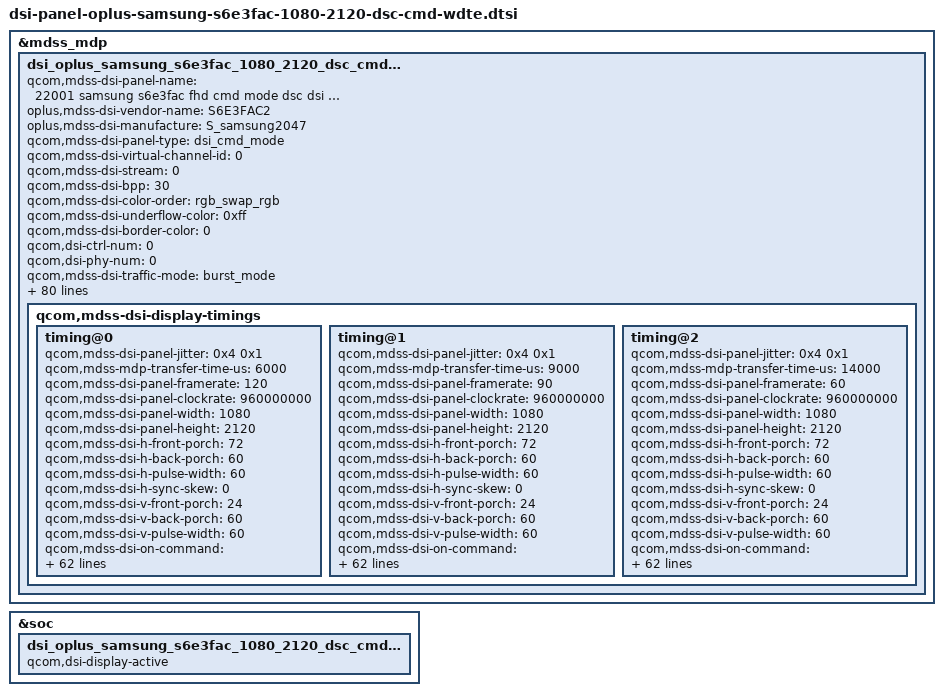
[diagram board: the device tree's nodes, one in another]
&mdss_mdp {
	dsi_oplus_samsung_s6e3fac_1080_2120_dsc_cmd_wdte: qcom,mdss_dsi_oplus_samsung_s6e3fac_1080_2120_dsc_cmd_wdte {
		qcom,mdss-dsi-panel-name = "22001 samsung s6e3fac fhd cmd mode dsc dsi panel";
		oplus,mdss-dsi-vendor-name = "S6E3FAC2";
		oplus,mdss-dsi-manufacture = "S_samsung2047";

		qcom,mdss-dsi-panel-type = "dsi_cmd_mode";
		qcom,mdss-dsi-virtual-channel-id = <0>;
		qcom,mdss-dsi-stream = <0>;
		qcom,mdss-dsi-bpp = <30>;
		qcom,mdss-dsi-color-order = "rgb_swap_rgb";
		qcom,mdss-dsi-underflow-color = <0xff>;
		qcom,mdss-dsi-border-color = <0>;
		qcom,dsi-ctrl-num = <0>;
		qcom,dsi-phy-num = <0>;
		qcom,mdss-dsi-traffic-mode = "burst_mode";
		qcom,mdss-dsi-lane-map = "lane_map_0123";
		qcom,mdss-dsi-bllp-eof-power-mode;
		qcom,mdss-dsi-bllp-power-mode;
		qcom,mdss-dsi-lane-0-state;
		qcom,mdss-dsi-lane-1-state;
		qcom,mdss-dsi-lane-2-state;
		qcom,mdss-dsi-lane-3-state;
		qcom,mdss-dsi-dma-trigger = "trigger_sw";
		qcom,mdss-loading-effect;
		qcom,mdss-dsi-mdp-trigger = "none";
		qcom,mdss-dsi-reset-sequence = <1 10>, <0 10>, <1 10>;
		qcom,mdss-dsi-te-pin-select = <1>;
		qcom,mdss-dsi-te-dcs-command = <1>;
		qcom,mdss-pan-physical-width-dimension = <64>;
		qcom,mdss-pan-physical-height-dimension = <125>;
		qcom,mdss-dsi-init-delay-us = <1000>;
		qcom,mdss-dsi-te-check-enable;
		qcom,mdss-dsi-te-using-te-pin;
		qcom,mdss-dsi-lp11-init;
		qcom,mdss-dsi-wr-mem-start = <0x2c>;
		qcom,mdss-dsi-wr-mem-continue = <0x3c>;
		qcom,mdss-dsi-panel-jitter = <0x4 0x1>;
		/* HDR Setting */
		qcom,mdss-dsi-panel-hdr-enabled;
		qcom,mdss-dsi-panel-hdr-color-primaries = <15635 16450 34000 16000 13250 34500 7500 3000>;
		qcom,mdss-dsi-panel-peak-brightness = <5400000>;
		qcom,mdss-dsi-panel-average-brightness = <2000000>;
		qcom,mdss-dsi-panel-blackness-level = <4000>;

		qcom,mdss-dsi-display-timings {
			timing@0{
				qcom,mdss-dsi-panel-jitter = <0x4 0x1>;
				qcom,mdss-mdp-transfer-time-us = <6000>;
				qcom,mdss-dsi-panel-framerate = <120>;
				qcom,mdss-dsi-panel-clockrate = <960000000>;
				qcom,mdss-dsi-panel-width = <1080>;
				qcom,mdss-dsi-panel-height = <2120>;
				qcom,mdss-dsi-h-front-porch = <72>;
				qcom,mdss-dsi-h-back-porch = <60>;
				qcom,mdss-dsi-h-pulse-width = <60>;
				qcom,mdss-dsi-h-sync-skew = <0>;
				qcom,mdss-dsi-v-front-porch = <24>;
				qcom,mdss-dsi-v-back-porch = <60>;
				qcom,mdss-dsi-v-pulse-width = <60>;

				qcom,mdss-dsi-on-command = [
					/* DSC Setting */
					39 01 00 00 00 00 02 9D 01
					39 01 00 00 00 00 5A 9E
					   11 00 00 89 30 80 08 48 04 38
					   00 28 02 1C 02 1C 02 00 02 3B
					   00 20 03 92 00 07 00 0E 02 E0
					   02 8B 18 00 10 F0 03 0C 20 00
					   06 0B 0B 33 0E 1C 2A 38 46 54
					   62 69 70 77 79 7B 7D 7E 01 02
					   01 00 09 40 09 BE 19 FC 19 FA
					   19 F8 1A 38 1A 78 1A B6 2A B6
					   2A F4 2A F4 4B 34 63 74 00
					/* Sleep Out(11h) */
					05 01 00 00 78 00 01 11
					/* TE ON */
					15 01 00 00 00 00 02 35 00
					/* CASET/PASET Setting */
					39 01 00 00 00 00 05 2A 00 00 04 37
					39 01 00 00 00 00 05 2B 00 00 08 47
					/* 120hz Transition */
					39 01 00 00 00 00 03 F0 5A 5A
					39 01 00 00 00 00 02 60 00
					39 01 00 00 00 00 02 F7 0F
					39 01 00 00 00 00 03 F0 A5 A5
					/* Brightness Control */
					39 01 00 00 00 00 03 F0 5A 5A
					15 01 00 00 00 00 02 53 20
					15 01 00 00 00 00 02 F7 0F
					39 01 00 00 00 00 03 F0 A5 A5
					/* auto flash */
					//39 01 00 00 00 00 03 F0 5A 5A
					//39 01 00 00 00 00 02 BF 02
					//39 01 00 00 00 00 03 F0 A5 A5
					/* Display On */
					//05 01 00 00 14 00 01 29
				];
				qcom,mdss-dsi-timing-switch-command = [
					/* 120hz Transition */
					39 01 00 00 00 00 03 F0 5A 5A
					39 01 00 00 00 00 02 60 00
					39 01 00 00 00 00 02 F7 0F
					39 01 00 00 10 00 03 F0 A5 A5
				];
				qcom,mdss-dsi-post-on-backlight = [
					/* Display On */
					05 01 00 00 00 00 01 29
				];
				qcom,mdss-dsi-off-command = [
					/* Display Off */
					05 01 00 00 14 00 01 28
					05 01 00 00 79 00 01 10
				];

				qcom,mdss-dsi-lp1-command = [
					05 00 00 00 09 00 01 28
					/* AOD Mode ON Setting */
					39 00 00 40 00 00 03 F0 5A 5A
					15 00 00 40 00 00 02 53 24
					39 00 00 40 00 00 03 51 07 FF
					15 00 00 40 00 00 02 F7 0F
					39 00 00 00 00 00 03 F0 A5 A5
					05 00 00 00 00 00 01 29
				];
				qcom,mdss-dsi-nolp-command = [
					05 00 00 00 09 00 01 28
					/* AOD Mode OFF Setting */
					39 00 00 40 00 00 03 F0 5A 5A
					15 00 00 40 00 00 02 60 00
					15 00 00 40 00 00 02 53 20
					39 00 00 40 00 00 03 51 00 00
					15 00 00 40 00 00 02 F7 0F
					39 00 00 00 00 00 03 F0 A5 A5
					05 00 00 00 00 00 01 29
				];
				qcom,mdss-dsi-aod-high-mode-command = [
					/* AOD High Mode, 50nit */
					39 00 00 40 00 00 03 F0 5A 5A
					39 00 00 40 00 00 03 51 07 FF
					15 00 00 40 00 00 02 F7 0F
					39 00 00 00 00 00 03 F0 A5 A5
				];
				qcom,mdss-dsi-aod-low-mode-command = [
					/* AOD Low Mode 10nit */
					39 00 00 40 00 00 03 F0 5A 5A
					39 00 00 40 00 00 03 51 01 AA
					15 00 00 40 00 00 02 F7 0F
					39 00 00 00 00 00 03 F0 A5 A5
				];

				qcom,mdss-dsi-loading-effect-1-command = [
					/* LOADING 100% */
					39 00 00 40 00 00 03 F0 5A 5A
					39 00 00 40 00 00 04 B0 02 79 92
					39 00 00 40 00 00 02 92 27
					39 00 00 40 00 00 04 B0 02 88 92
					39 00 00 40 00 00 10 92 05 06 05 17 19 16 1F 21 1E 25 27 24 27 2A 26
					39 00 00 40 00 00 04 B0 03 61 92
					39 00 00 40 00 00 12 92 E2 0E 0E 0E 92 1D 98 80 00 00 00 00 FF 90 00 00 01
					39 00 00 00 00 00 03 F0 A5 A5
				];
				qcom,mdss-dsi-loading-effect-2-command = [
					/* LOADING 110% */
					39 00 00 40 00 00 03 F0 5A 5A
					39 00 00 40 00 00 04 B0 02 79 92
					39 00 00 40 00 00 02 92 27
					39 00 00 40 00 00 04 B0 02 88 92
					39 00 00 40 00 00 10 92 05 06 05 17 19 16 1F 21 1E 25 27 24 27 2A 26
					39 00 00 40 00 00 04 B0 03 61 92
					39 00 00 40 00 00 12 92 E2 09 09 09 92 1D 98 80 76 5E 5B 49 FF 90 00 00 01
					39 00 00 00 00 00 03 F0 A5 A5
				];
				qcom,mdss-dsi-loading-effect-off-command = [
					/* LOADING off */
					39 00 00 40 00 00 03 F0 5A 5A
					39 00 00 40 00 00 04 B0 02 79 92
					39 00 00 40 00 00 02 92 07
					39 00 00 00 00 00 03 F0 A5 A5
				];

				qcom,mdss-dsi-panel-read-register-open-command = [
				];
				qcom,mdss-dsi-panel-read-register-close-command = [
				];

				qcom,mdss-dsi-lp1-command-state = "dsi_hs_mode";
				qcom,mdss-dsi-nolp-command-state = "dsi_hs_mode";
				qcom,mdss-dsi-aod-high-mode-command-state = "dsi_hs_mode";
				qcom,mdss-dsi-aod-low-mode-command-state = "dsi_hs_mode";
				qcom,mdss-dsi-loading-effect-1-command-state = "dsi_hs_mode";
				qcom,mdss-dsi-loading-effect-2-command-state = "dsi_hs_mode";
				qcom,mdss-dsi-loading-effect-off-command-state = "dsi_hs_mode";
				qcom,mdss-dsi-post-on-backlight-state = "dsi_hs_mode";
				qcom,mdss-dsi-on-command-state = "dsi_hs_mode";
				qcom,mdss-dsi-off-command-state = "dsi_hs_mode";
				qcom,mdss-dsi-osc-clk-mode0-command-state = "dsi_hs_mode";
				qcom,mdss-dsi-osc-clk-mode1-command-state = "dsi_hs_mode";

				qcom,compression-mode = "dsc";
				qcom,mdss-dsc-slice-height = <40>;
				qcom,mdss-dsc-slice-width = <540>;
				qcom,mdss-dsc-slice-per-pkt = <2>;
				qcom,mdss-dsc-bit-per-component = <8>;
				qcom,mdss-dsc-bit-per-pixel = <8>;
				qcom,mdss-dsc-block-prediction-enable;
				qcom,mdss-dsi-panel-id1-command-state = "dsi_lp_mode";
				qcom,mdss-dsi-panel-read-register-open-state = "dsi_hs_mode";
				qcom,mdss-dsi-panel-read-register-close-state = "dsi_hs_mode";
			};
			timing@1{
				qcom,mdss-dsi-panel-jitter = <0x4 0x1>;
				qcom,mdss-mdp-transfer-time-us = <9000>;
				qcom,mdss-dsi-panel-framerate = <90>;
				qcom,mdss-dsi-panel-clockrate = <960000000>;
				qcom,mdss-dsi-panel-width = <1080>;
				qcom,mdss-dsi-panel-height = <2120>;
				qcom,mdss-dsi-h-front-porch = <72>;
				qcom,mdss-dsi-h-back-porch = <60>;
				qcom,mdss-dsi-h-pulse-width = <60>;
				qcom,mdss-dsi-h-sync-skew = <0>;
				qcom,mdss-dsi-v-front-porch = <24>;
				qcom,mdss-dsi-v-back-porch = <60>;
				qcom,mdss-dsi-v-pulse-width = <60>;

				qcom,mdss-dsi-on-command = [
					/* DSC Setting */
					39 01 00 00 00 00 02 9D 01
					39 01 00 00 00 00 5A 9E
					   11 00 00 89 30 80 08 48 04 38
					   00 28 02 1C 02 1C 02 00 02 3B
					   00 20 03 92 00 07 00 0E 02 E0
					   02 8B 18 00 10 F0 03 0C 20 00
					   06 0B 0B 33 0E 1C 2A 38 46 54
					   62 69 70 77 79 7B 7D 7E 01 02
					   01 00 09 40 09 BE 19 FC 19 FA
					   19 F8 1A 38 1A 78 1A B6 2A B6
					   2A F4 2A F4 4B 34 63 74 00
					/* Sleep Out(11h) */
					05 01 00 00 78 00 01 11
					/* TE ON */
					15 01 00 00 00 00 02 35 00
					/* CASET/PASET Setting */
					39 01 00 00 00 00 05 2A 00 00 04 37
					39 01 00 00 00 00 05 2B 00 00 08 47
					/* 90hz Transition */
					39 01 00 00 00 00 03 F0 5A 5A
					39 01 00 00 00 00 02 60 10
					39 01 00 00 00 00 02 F7 0F
					39 01 00 00 00 00 03 F0 A5 A5
					/* Brightness Control */
					39 01 00 00 00 00 03 F0 5A 5A
					15 01 00 00 00 00 02 53 20
					15 01 00 00 00 00 02 F7 0F
					39 01 00 00 00 00 03 F0 A5 A5
					/* auto flash */
					//39 01 00 00 00 00 03 F0 5A 5A
					//39 01 00 00 00 00 02 BF 02
					//39 01 00 00 00 00 03 F0 A5 A5
					/* Display On */
					//05 01 00 00 14 00 01 29
				];
				qcom,mdss-dsi-timing-switch-command = [
					/* 90hz Transition */
					39 01 00 00 00 00 03 F0 5A 5A
					39 01 00 00 00 00 02 60 10
					39 01 00 00 00 00 02 F7 0F
					39 01 00 00 10 00 03 F0 A5 A5
				];
				qcom,mdss-dsi-post-on-backlight = [
					/* Display On */
					05 01 00 00 00 00 01 29
				];
				qcom,mdss-dsi-off-command = [
					/* Display Off */
					05 01 00 00 14 00 01 28
					05 01 00 00 79 00 01 10
				];

				qcom,mdss-dsi-lp1-command = [
					05 00 00 00 0C 00 01 28
					/* AOD Mode ON Setting */
					39 00 00 40 00 00 03 F0 5A 5A
					15 00 00 40 00 00 02 53 24
					39 00 00 40 00 00 03 51 07 FF
					15 00 00 40 00 00 02 F7 0F
					39 00 00 00 00 00 03 F0 A5 A5
					05 00 00 00 00 00 01 29
				];
				qcom,mdss-dsi-nolp-command = [
					05 00 00 00 0C 00 01 28
					/* AOD Mode OFF Setting */
					39 00 00 40 00 00 03 F0 5A 5A
					15 00 00 40 00 00 02 60 10
					15 00 00 40 00 00 02 53 20
					39 00 00 40 00 00 03 51 00 00
					15 00 00 40 00 00 02 F7 0F
					39 00 00 00 00 00 03 F0 A5 A5
					05 00 00 00 00 00 01 29
				];
				qcom,mdss-dsi-aod-high-mode-command = [
					/* AOD High Mode, 50nit */
					39 00 00 40 00 00 03 F0 5A 5A
					39 00 00 40 00 00 03 51 07 FF
					15 00 00 40 00 00 02 F7 0F
					39 00 00 00 00 00 03 F0 A5 A5
				];
				qcom,mdss-dsi-aod-low-mode-command = [
					/* AOD Low Mode 10nit */
					39 00 00 40 00 00 03 F0 5A 5A
					39 00 00 40 00 00 03 51 01 AA
					15 00 00 40 00 00 02 F7 0F
					39 00 00 00 00 00 03 F0 A5 A5
				];

				qcom,mdss-dsi-loading-effect-1-command = [
					/* LOADING 100% */
					39 00 00 40 00 00 03 F0 5A 5A
					39 00 00 40 00 00 04 B0 02 79 92
					39 00 00 40 00 00 02 92 27
					39 00 00 40 00 00 04 B0 02 88 92
					39 00 00 40 00 00 10 92 05 06 05 17 19 16 1F 21 1E 25 27 24 27 2A 26
					39 00 00 40 00 00 04 B0 03 61 92
					39 00 00 40 00 00 12 92 E2 0E 0E 0E 92 1D 98 80 00 00 00 00 FF 90 00 00 01
					39 00 00 00 00 00 03 F0 A5 A5
				];
				qcom,mdss-dsi-loading-effect-2-command = [
					/* LOADING 110% */
					39 00 00 40 00 00 03 F0 5A 5A
					39 00 00 40 00 00 04 B0 02 79 92
					39 00 00 40 00 00 02 92 27
					39 00 00 40 00 00 04 B0 02 88 92
					39 00 00 40 00 00 10 92 05 06 05 17 19 16 1F 21 1E 25 27 24 27 2A 26
					39 00 00 40 00 00 04 B0 03 61 92
					39 00 00 40 00 00 12 92 E2 09 09 09 92 1D 98 80 76 5E 5B 49 FF 90 00 00 01
					39 00 00 00 00 00 03 F0 A5 A5
				];
				qcom,mdss-dsi-loading-effect-off-command = [
					/* LOADING off */
					39 00 00 40 00 00 03 F0 5A 5A
					39 00 00 40 00 00 04 B0 02 79 92
					39 00 00 40 00 00 02 92 07
					39 00 00 00 00 00 03 F0 A5 A5
				];
				qcom,mdss-dsi-panel-read-register-open-command = [
				];
				qcom,mdss-dsi-panel-read-register-close-command = [
				];

				qcom,mdss-dsi-lp1-command-state = "dsi_hs_mode";
				qcom,mdss-dsi-nolp-command-state = "dsi_hs_mode";
				qcom,mdss-dsi-aod-high-mode-command-state = "dsi_hs_mode";
				qcom,mdss-dsi-aod-low-mode-command-state = "dsi_hs_mode";
				qcom,mdss-dsi-loading-effect-1-command-state = "dsi_hs_mode";
				qcom,mdss-dsi-loading-effect-2-command-state = "dsi_hs_mode";
				qcom,mdss-dsi-loading-effect-off-command-state = "dsi_hs_mode";
				qcom,mdss-dsi-post-on-backlight-state = "dsi_hs_mode";
				qcom,mdss-dsi-on-command-state = "dsi_hs_mode";
				qcom,mdss-dsi-off-command-state = "dsi_hs_mode";
				qcom,mdss-dsi-osc-clk-mode0-command-state = "dsi_hs_mode";
				qcom,mdss-dsi-osc-clk-mode1-command-state = "dsi_hs_mode";

				qcom,compression-mode = "dsc";
				qcom,mdss-dsc-slice-height = <40>;
				qcom,mdss-dsc-slice-width = <540>;
				qcom,mdss-dsc-slice-per-pkt = <2>;
				qcom,mdss-dsc-bit-per-component = <8>;
				qcom,mdss-dsc-bit-per-pixel = <8>;
				qcom,mdss-dsc-block-prediction-enable;
				qcom,mdss-dsi-panel-id1-command-state = "dsi_lp_mode";
				qcom,mdss-dsi-panel-read-register-open-state = "dsi_hs_mode";
				qcom,mdss-dsi-panel-read-register-close-state = "dsi_hs_mode";
			};
			timing@2{
				qcom,mdss-dsi-panel-jitter = <0x4 0x1>;
				qcom,mdss-mdp-transfer-time-us = <14000>;
				qcom,mdss-dsi-panel-framerate = <60>;
				qcom,mdss-dsi-panel-clockrate = <960000000>;
				qcom,mdss-dsi-panel-width = <1080>;
				qcom,mdss-dsi-panel-height = <2120>;
				qcom,mdss-dsi-h-front-porch = <72>;
				qcom,mdss-dsi-h-back-porch = <60>;
				qcom,mdss-dsi-h-pulse-width = <60>;
				qcom,mdss-dsi-h-sync-skew = <0>;
				qcom,mdss-dsi-v-front-porch = <24>;
				qcom,mdss-dsi-v-back-porch = <60>;
				qcom,mdss-dsi-v-pulse-width = <60>;

				qcom,mdss-dsi-on-command = [
					/* DSC Setting */
					39 01 00 00 00 00 02 9D 01
					39 01 00 00 00 00 5A 9E
					   11 00 00 89 30 80 08 48 04 38
					   00 28 02 1C 02 1C 02 00 02 3B
					   00 20 03 92 00 07 00 0E 02 E0
					   02 8B 18 00 10 F0 03 0C 20 00
					   06 0B 0B 33 0E 1C 2A 38 46 54
					   62 69 70 77 79 7B 7D 7E 01 02
					   01 00 09 40 09 BE 19 FC 19 FA
					   19 F8 1A 38 1A 78 1A B6 2A B6
					   2A F4 2A F4 4B 34 63 74 00
					/* Sleep Out(11h) */
					05 01 00 00 78 00 01 11
					/* TE ON */
					15 01 00 00 00 00 02 35 00
					/* CASET/PASET Setting */
					39 01 00 00 00 00 05 2A 00 00 04 37
					39 01 00 00 00 00 05 2B 00 00 08 47
					/* 60hz Transition */
					39 01 00 00 00 00 03 F0 5A 5A
					39 01 00 00 00 00 02 60 18
					39 01 00 00 00 00 02 F7 0F
					39 01 00 00 00 00 03 F0 A5 A5
					/* Brightness Control */
					39 01 00 00 00 00 03 F0 5A 5A
					15 01 00 00 00 00 02 53 20
					15 01 00 00 00 00 02 F7 0F
					39 01 00 00 00 00 03 F0 A5 A5
					/* auto flash */
					//39 01 00 00 00 00 03 F0 5A 5A
					//39 01 00 00 00 00 02 BF 02
					//39 01 00 00 00 00 03 F0 A5 A5
					/* Display On */
					//05 01 00 00 14 00 01 29
				];
				qcom,mdss-dsi-timing-switch-command = [
					/* 60hz Transition */
					39 01 00 00 00 00 03 F0 5A 5A
					39 01 00 00 00 00 02 60 18
					39 01 00 00 00 00 02 F7 0F
					39 01 00 00 10 00 03 F0 A5 A5
				];
				qcom,mdss-dsi-post-on-backlight = [
					/* Display On */
					05 01 00 00 00 00 01 29
				];
				qcom,mdss-dsi-off-command = [
					/* Display Off */
					05 01 00 00 14 00 01 28
					05 01 00 00 79 00 01 10
				];

				qcom,mdss-dsi-lp1-command = [
					05 00 00 00 11 00 01 28
					/* AOD Mode ON Setting */
					39 00 00 40 00 00 03 F0 5A 5A
					15 00 00 40 00 00 02 53 24
					39 00 00 40 00 00 03 51 07 FF
					15 00 00 40 00 00 02 F7 0F
					39 00 00 00 00 00 03 F0 A5 A5
					05 00 00 00 00 00 01 29
				];
				qcom,mdss-dsi-nolp-command = [
					05 00 00 00 11 00 01 28
					/* AOD Mode OFF Setting */
					39 00 00 40 00 00 03 F0 5A 5A
					15 00 00 40 00 00 02 60 18
					15 00 00 40 00 00 02 53 20
					39 00 00 40 00 00 03 51 00 00
					15 00 00 40 00 00 02 F7 0F
					39 00 00 00 00 00 03 F0 A5 A5
					05 00 00 00 00 00 01 29
				];
				qcom,mdss-dsi-aod-high-mode-command = [
					/* AOD High Mode, 50nit */
					39 00 00 40 00 00 03 F0 5A 5A
					39 00 00 40 00 00 03 51 07 FF
					15 00 00 40 00 00 02 F7 0F
					39 00 00 00 00 00 03 F0 A5 A5
				];
				qcom,mdss-dsi-aod-low-mode-command = [
					/* AOD Low Mode 10nit */
					39 00 00 40 00 00 03 F0 5A 5A
					39 00 00 40 00 00 03 51 01 AA
					15 00 00 40 00 00 02 F7 0F
					39 00 00 00 00 00 03 F0 A5 A5
				];

				qcom,mdss-dsi-loading-effect-1-command = [
					/* LOADING 100% */
					39 00 00 40 00 00 03 F0 5A 5A
					39 00 00 40 00 00 04 B0 02 79 92
					39 00 00 40 00 00 02 92 27
					39 00 00 40 00 00 04 B0 02 88 92
					39 00 00 40 00 00 10 92 05 06 05 17 19 16 1F 21 1E 25 27 24 27 2A 26
					39 00 00 40 00 00 04 B0 03 61 92
					39 00 00 40 00 00 12 92 E2 0E 0E 0E 92 1D 98 80 00 00 00 00 FF 90 00 00 01
					39 00 00 00 00 00 03 F0 A5 A5
				];
				qcom,mdss-dsi-loading-effect-2-command = [
					/* LOADING 110% */
					39 00 00 40 00 00 03 F0 5A 5A
					39 00 00 40 00 00 04 B0 02 79 92
					39 00 00 40 00 00 02 92 27
					39 00 00 40 00 00 04 B0 02 88 92
					39 00 00 40 00 00 10 92 05 06 05 17 19 16 1F 21 1E 25 27 24 27 2A 26
					39 00 00 40 00 00 04 B0 03 61 92
					39 00 00 40 00 00 12 92 E2 09 09 09 92 1D 98 80 76 5E 5B 49 FF 90 00 00 01
					39 00 00 00 00 00 03 F0 A5 A5
				];
				qcom,mdss-dsi-loading-effect-off-command = [
					/* LOADING off */
					39 00 00 40 00 00 03 F0 5A 5A
					39 00 00 40 00 00 04 B0 02 79 92
					39 00 00 40 00 00 02 92 07
					39 00 00 00 00 00 03 F0 A5 A5
				];

				qcom,mdss-dsi-panel-read-register-open-command = [
				];
				qcom,mdss-dsi-panel-read-register-close-command = [
				];

				qcom,mdss-dsi-lp1-command-state = "dsi_hs_mode";
				qcom,mdss-dsi-nolp-command-state = "dsi_hs_mode";
				qcom,mdss-dsi-aod-high-mode-command-state = "dsi_hs_mode";
				qcom,mdss-dsi-aod-low-mode-command-state = "dsi_hs_mode";
				qcom,mdss-dsi-loading-effect-1-command-state = "dsi_hs_mode";
				qcom,mdss-dsi-loading-effect-2-command-state = "dsi_hs_mode";
				qcom,mdss-dsi-loading-effect-off-command-state = "dsi_hs_mode";
				qcom,mdss-dsi-post-on-backlight-state = "dsi_hs_mode";
				qcom,mdss-dsi-on-command-state = "dsi_hs_mode";
				qcom,mdss-dsi-off-command-state = "dsi_hs_mode";
				qcom,mdss-dsi-osc-clk-mode0-command-state = "dsi_hs_mode";
				qcom,mdss-dsi-osc-clk-mode1-command-state = "dsi_hs_mode";

				qcom,compression-mode = "dsc";
				qcom,mdss-dsc-slice-height = <40>;
				qcom,mdss-dsc-slice-width = <540>;
				qcom,mdss-dsc-slice-per-pkt = <2>;
				qcom,mdss-dsc-bit-per-component = <8>;
				qcom,mdss-dsc-bit-per-pixel = <8>;
				qcom,mdss-dsc-block-prediction-enable;
				qcom,mdss-dsi-panel-id1-command-state = "dsi_lp_mode";
				qcom,mdss-dsi-panel-read-register-open-state = "dsi_hs_mode";
				qcom,mdss-dsi-panel-read-register-close-state = "dsi_hs_mode";
			};
		};
	};
};

&soc {
	dsi_oplus_samsung_s6e3fac_1080_2120_dsc_cmd_wdte {
		qcom,dsi-display-active;
	};
};

&dsi_oplus_samsung_s6e3fac_1080_2120_dsc_cmd_wdte {
	qcom,panel-supply-entries = <&dsi_panel_oplus_optimization_pwr_supply>;
	qcom,panel-sec-supply-entries = <&dsi_panel_oplus_pwr_supply_sec>;
	qcom,mdss-dsi-panel-controller = <&mdss_dsi1>;

	/* hardware config */
	qcom,platform-te-gpio = <&tlmm 87 0>;
	qcom,platform-sec-reset-gpio = <&tlmm 22 0>;
	qcom,platform-panel-vout-gpio = <&tlmm 90 0>;
	qcom,ulps-enabled;
	qcom,dsi-sec-ctrl-num = <0x1>;
	qcom,dsi-sec-phy-num = <0x1>;
	qcom,dsi-select-sec-clocks = "pll_byte_clk1", "pll_dsi_clk1";
	qcom,mdss-dsi-te-using-wd;

	/* backlight config*/
	qcom,mdss-dsi-bl-pmic-control-type = "bl_ctrl_dcs";
	qcom,mdss-dsi-sec-bl-pmic-control-type = "bl_ctrl_dcs";
	qcom,mdss-dsi-bl-inverted-dbv;
	qcom,mdss-dsi-bl-min-level = <1>;
	qcom,mdss-dsi-bl-max-level = <4095>;
	qcom,mdss-brightness-max-level = <4095>;
	oplus,dsi-bl-normal-max-level = <2047>;
	oplus,dsi-brightness-normal-max-level = <2047>;
	oplus,dsi-brightness-default-level = <1600>;

	/* ofp config */
	oplus,ofp-fp-type = <0x02>;

	/*esd config*/
	qcom,esd-check-enabled;
	qcom,mdss-dsi-panel-status-check-mode = "reg_read";
	qcom,mdss-dsi-panel-status-command = [
			06 01 00 01 01 00 02 0A 00
			06 01 00 01 01 00 02 0E 00
		];
	qcom,mdss-dsi-panel-status-command-state = "dsi_lp_mode";
	qcom,mdss-dsi-panel-status-value = <0x9F 0x80>;
	qcom,mdss-dsi-panel-status-read-length = <1 1>;


	/* serial num config */
	oplus,dsi-serial-number-enabled;
	oplus,dsi-serial-number-lock;
	oplus,dsi-serial-number-reg= <0xD8>;
	oplus,dsi-serial-number-index= <7>;
	oplus,dsi-serial-number-read-count= <15>;

	/* color calibration config */
	oplus,color_vivid_status;
	oplus,color_srgb_status;
	//oplus,color_softiris_status;
	oplus,color_dual_panel_status;
	oplus,color_dual_brightness_status;
	oplus,color_oplus_calibrate_status;

	qcom,mdss-dsi-display-timings {
		timing@0 { /* FHD+ 120hz 480Mhz */
			qcom,mdss-dsi-panel-phy-timings = [00 1E 08 07 18 22 08 08 09 02 04 00 1A 0D];
			qcom,display-topology = <1 1 1>,<2 2 1>;
			qcom,default-topology-index = <1>;
		};

		timing@1 { /* FHD+ 90hz 480Mhz */
			qcom,mdss-dsi-panel-phy-timings = [00 1E 08 07 18 22 08 08 09 02 04 00 1A 0D];
			qcom,display-topology = <1 1 1>,<2 2 1>;
			qcom,default-topology-index = <1>;
		};

		timing@2 { /* FHD+ 60hz 480Mhz */
			qcom,mdss-dsi-panel-phy-timings = [00 1E 08 07 18 22 08 08 09 02 04 00 1A 0D];
			qcom,display-topology = <1 1 1>,<2 2 1>;
			qcom,default-topology-index = <1>;
		};

	};
};

&dsi_oplus_samsung_s6e3fac_1080_2120_dsc_cmd_wdte {
	qcom,panel_voltage_vddi_name = "vddio";
	qcom,panel_voltage_vddi = <0 1800000 1850000 1950000>;
	qcom,panel_voltage_vddr_name = "vddio";
	qcom,panel_voltage_vddr = <1 1800000 1850000 1950000>;
};

